# ATSAMA5D27WLSOM1 device description
Architecture: CORTEX-A5; Family: SAMA5; Series: SAMA5D2
Registers are 32-bit, read-write, no defined reset value unless marked. A register's access mark holds for its fields unless they carry their own. Offsets are from the block's base; [hi:lo] are bit positions; {n}, {i} and the like mark numbered series; 'fields as' and 'values as' point back to an identical list.

## LCDC — LCD Controller
Instances: LCDC 0xF0000000
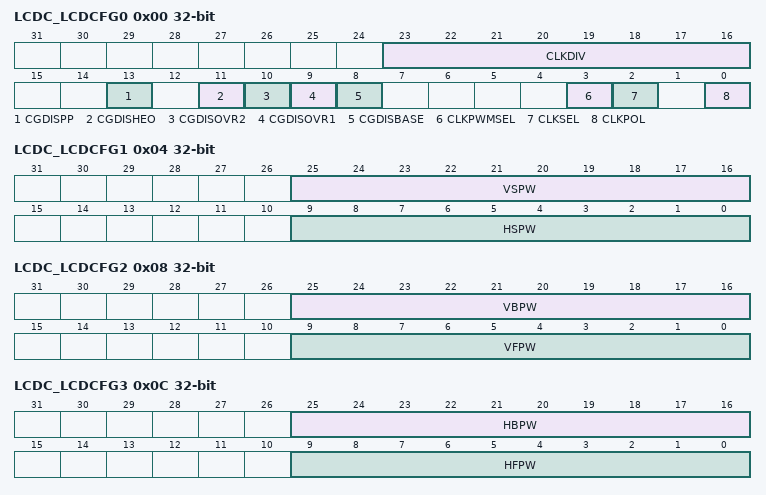
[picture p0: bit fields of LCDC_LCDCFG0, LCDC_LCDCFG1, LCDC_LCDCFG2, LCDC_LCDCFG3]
0x00 LCDC_LCDCFG0 — LCD Controller Configuration Register 0
  [23:16] CLKDIV — LCD Controller Clock Divider
  [13] CGDISPP — Clock Gating Disable Control for the Post Processing Layer
  [11] CGDISHEO — Clock Gating Disable Control for the High-End Overlay
  [10] CGDISOVR2 — Clock Gating Disable Control for the Overlay 2 Layer
  [9] CGDISOVR1 — Clock Gating Disable Control for the Overlay 1 Layer
  [8] CGDISBASE — Clock Gating Disable Control for the Base Layer
  [3] CLKPWMSEL — LCD Controller PWM Clock Source Selection
  [2] CLKSEL — LCD Controller Clock Source Selection
  [0] CLKPOL — LCD Controller Clock Polarity
0x04 LCDC_LCDCFG1 — LCD Controller Configuration Register 1
  [25:16] VSPW — Vertical Synchronization Pulse Width
  [9:0] HSPW — Horizontal Synchronization Pulse Width
0x08 LCDC_LCDCFG2 — LCD Controller Configuration Register 2
  [25:16] VBPW — Vertical Back Porch Width
  [9:0] VFPW — Vertical Front Porch Width
0x0C LCDC_LCDCFG3 — LCD Controller Configuration Register 3
  [25:16] HBPW — Horizontal Back Porch Width
  [9:0] HFPW — Horizontal Front Porch Width
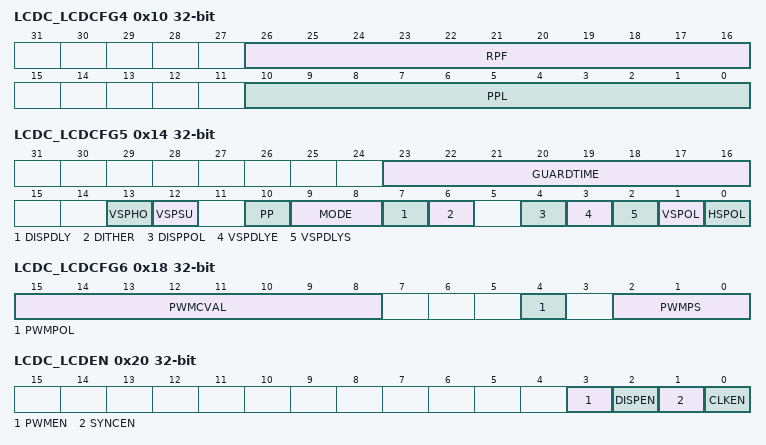
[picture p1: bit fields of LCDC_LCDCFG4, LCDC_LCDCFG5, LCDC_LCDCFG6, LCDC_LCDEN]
0x10 LCDC_LCDCFG4 — LCD Controller Configuration Register 4
  [26:16] RPF — Number of Active Row Per Frame
  [10:0] PPL — Number of Pixels Per Line
0x14 LCDC_LCDCFG5 — LCD Controller Configuration Register 5
  [23:16] GUARDTIME — LCD DISPLAY Guard Time
  [13] VSPHO — LCD Controller Vertical synchronization Pulse Hold Configuration
  [12] VSPSU — LCD Controller Vertical synchronization Pulse Setup Configuration
  [10] PP — Post Processing Enable
  [9:8] MODE — LCD Controller Output Mode
    0=OUTPUT_12BPP (LCD Output mode is set to 12 bits per pixel); 1=OUTPUT_16BPP (LCD Output mode is set to 16 bits per pixel); 2=OUTPUT_18BPP (LCD Output mode is set to 18 bits per pixel); 3=OUTPUT_24BPP (LCD Output mode is set to 24 bits per pixel)
  [7] DISPDLY — LCD Controller Display Power Signal Synchronization
  [6] DITHER — LCD Controller Dithering
  [4] DISPPOL — Display Signal Polarity
  [3] VSPDLYE — Vertical Synchronization Pulse End
  [2] VSPDLYS — Vertical Synchronization Pulse Start
  [1] VSPOL — Vertical Synchronization Pulse Polarity
  [0] HSPOL — Horizontal Synchronization Pulse Polarity
0x18 LCDC_LCDCFG6 — LCD Controller Configuration Register 6
  [15:8] PWMCVAL — LCD Controller PWM Compare Value
  [4] PWMPOL — LCD Controller PWM Signal Polarity
  [2:0] PWMPS — PWM Clock Prescaler
    0=DIV_1 (The counter advances at a rate of fCOUNTER = fPWM_SELECTED_CLOCK); 1=DIV_2 (The counter advances at a rate of fCOUNTER = fPWM_SELECTED_CLOCK/2); 2=DIV_4 (The counter advances at a rate of fCOUNTER = fPWM_SELECTED_CLOCK/4); 3=DIV_8 (The counter advances at a rate of fCOUNTER = fPWM_SELECTED_CLOCK/8); 4=DIV_16 (The counter advances at a rate of fCOUNTER = fPWM_SELECTED_CLOCK/16); 5=DIV_32 (The counter advances at a of rate fCOUNTER = fPWM_SELECTED_CLOCK/32); 6=DIV_64 (The counter advances at a of rate fCOUNTER = fPWM_SELECTED_CLOCK/64)
0x20 LCDC_LCDEN wo — LCD Controller Enable Register
  [3] PWMEN — LCD Controller Pulse Width Modulation Enable
  [2] DISPEN — LCD Controller DISP Signal Enable
  [1] SYNCEN — LCD Controller Horizontal and Vertical Synchronization Enable
  [0] CLKEN — LCD Controller Pixel Clock Enable
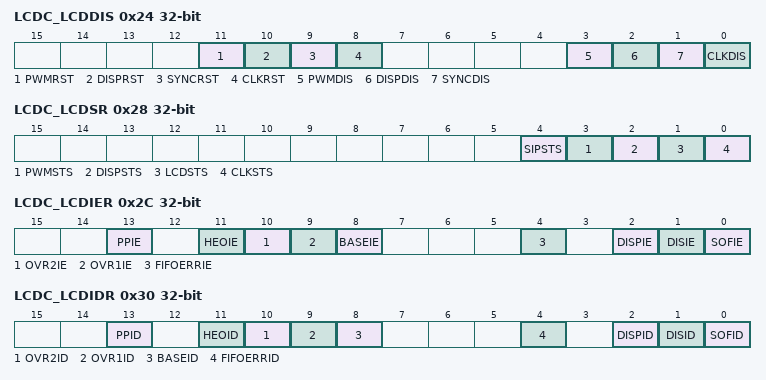
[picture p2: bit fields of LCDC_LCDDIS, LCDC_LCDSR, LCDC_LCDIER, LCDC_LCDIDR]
0x24 LCDC_LCDDIS wo — LCD Controller Disable Register
  [11] PWMRST — LCD Controller PWM Reset
  [10] DISPRST — LCD Controller DISP Signal Reset
  [9] SYNCRST — LCD Controller Horizontal and Vertical Synchronization Reset
  [8] CLKRST — LCD Controller Clock Reset
  [3] PWMDIS — LCD Controller Pulse Width Modulation Disable
  [2] DISPDIS — LCD Controller DISP Signal Disable
  [1] SYNCDIS — LCD Controller Horizontal and Vertical Synchronization Disable
  [0] CLKDIS — LCD Controller Pixel Clock Disable
0x28 LCDC_LCDSR ro — LCD Controller Status Register
  [4] SIPSTS — Synchronization In Progress
  [3] PWMSTS — LCD Controller PWM Signal Status
  [2] DISPSTS — LCD Controller DISP Signal Status
  [1] LCDSTS — LCD Controller Synchronization status
  [0] CLKSTS — Clock Status
0x2C LCDC_LCDIER wo — LCD Controller Interrupt Enable Register
  [13] PPIE — Post Processing Interrupt Enable
  [11] HEOIE — High-End Overlay Interrupt Enable
  [10] OVR2IE — Overlay 2 Interrupt Enable
  [9] OVR1IE — Overlay 1 Interrupt Enable
  [8] BASEIE — Base Layer Interrupt Enable
  [4] FIFOERRIE — Output FIFO Error Interrupt Enable
  [2] DISPIE — Powerup/Powerdown Sequence Terminated Interrupt Enable
  [1] DISIE — LCD Disable Interrupt Enable
  [0] SOFIE — Start of Frame Interrupt Enable
0x30 LCDC_LCDIDR wo — LCD Controller Interrupt Disable Register
  [13] PPID — Post Processing Interrupt Disable
  [11] HEOID — High-End Overlay Interrupt Disable
  [10] OVR2ID — Overlay 2 Interrupt Disable
  [9] OVR1ID — Overlay 1 Interrupt Disable
  [8] BASEID — Base Layer Interrupt Disable
  [4] FIFOERRID — Output FIFO Error Interrupt Disable
  [2] DISPID — Powerup/Powerdown Sequence Terminated Interrupt Disable
  [1] DISID — LCD Disable Interrupt Disable
  [0] SOFID — Start of Frame Interrupt Disable
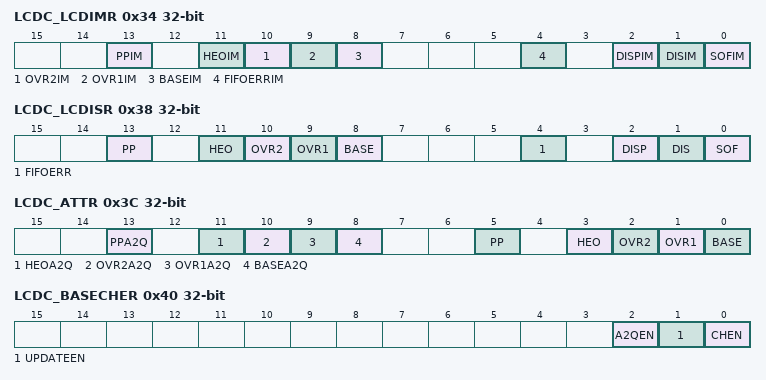
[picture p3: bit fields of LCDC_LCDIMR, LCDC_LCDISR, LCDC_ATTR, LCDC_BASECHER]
0x34 LCDC_LCDIMR ro — LCD Controller Interrupt Mask Register
  [13] PPIM — Post Processing Interrupt Mask
  [11] HEOIM — High-End Overlay Interrupt Mask
  [10] OVR2IM — Overlay 2 Interrupt Mask
  [9] OVR1IM — Overlay 1 Interrupt Mask
  [8] BASEIM — Base Layer Interrupt Mask
  [4] FIFOERRIM — Output FIFO Error Interrupt Mask
  [2] DISPIM — Powerup/Powerdown Sequence Terminated Interrupt Mask
  [1] DISIM — LCD Disable Interrupt Mask
  [0] SOFIM — Start of Frame Interrupt Mask
0x38 LCDC_LCDISR ro — LCD Controller Interrupt Status Register
  [13] PP — Post Processing Raw Interrupt Status
  [11] HEO — High-End Overlay Raw Interrupt Status
  [10] OVR2 — Overlay 2 Raw Interrupt Status
  [9] OVR1 — Overlay 1 Raw Interrupt Status
  [8] BASE — Base Layer Raw Interrupt Status
  [4] FIFOERR — Output FIFO Error
  [2] DISP — Powerup/Powerdown Sequence Terminated Interrupt Status
  [1] DIS — LCD Disable Interrupt Status
  [0] SOF — Start of Frame Interrupt Status
0x3C LCDC_ATTR wo — LCD Controller Attribute Register
  [13] PPA2Q — Post-Processing Update Add To Queue
  [11] HEOA2Q — High-End Overlay Update Add To Queue
  [10] OVR2A2Q — Overlay 2 Update Add to Queue
  [9] OVR1A2Q — Overlay 1 Update Add To Queue
  [8] BASEA2Q — Base Layer Update Add To Queue
  [5] PP — Post-Processing Update Attribute
  [3] HEO — High-End Overlay Update Attribute
  [2] OVR2 — Overlay 2 Update Attribute
  [1] OVR1 — Overlay 1 Update Attribute
  [0] BASE — Base Layer Update Attribute
0x40 LCDC_BASECHER wo — Base Layer Channel Enable Register
  [2] A2QEN — Add To Queue Enable
  [1] UPDATEEN — Update Overlay Attributes Enable
  [0] CHEN — Channel Enable
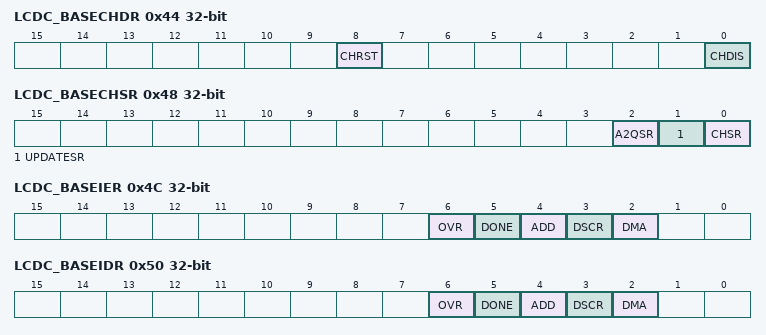
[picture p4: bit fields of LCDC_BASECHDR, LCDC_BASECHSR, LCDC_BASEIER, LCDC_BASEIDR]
0x44 LCDC_BASECHDR wo — Base Layer Channel Disable Register
  [8] CHRST — Channel Reset
  [0] CHDIS — Channel Disable
0x48 LCDC_BASECHSR ro — Base Layer Channel Status Register
  [2] A2QSR — Add To Queue Status
  [1] UPDATESR — Update Overlay Attributes In Progress Status
  [0] CHSR — Channel Status
0x4C LCDC_BASEIER wo — Base Layer Interrupt Enable Register
  [6] OVR — Overflow Interrupt Enable
  [5] DONE — End of List Interrupt Enable
  [4] ADD — Head Descriptor Loaded Interrupt Enable
  [3] DSCR — Descriptor Loaded Interrupt Enable
  [2] DMA — End of DMA Transfer Interrupt Enable
0x50 LCDC_BASEIDR wo — Base Layer Interrupt Disabled Register
  [6] OVR — Overflow Interrupt Disable
  [5] DONE — End of List Interrupt Disable
  [4] ADD — Head Descriptor Loaded Interrupt Disable
  [3] DSCR — Descriptor Loaded Interrupt Disable
  [2] DMA — End of DMA Transfer Interrupt Disable
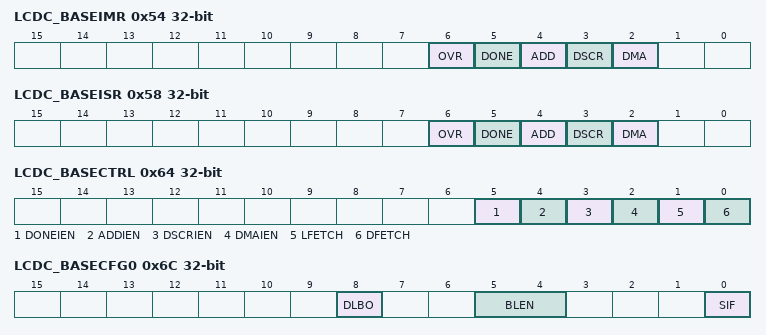
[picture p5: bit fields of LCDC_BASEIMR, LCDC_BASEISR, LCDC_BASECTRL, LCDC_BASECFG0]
0x54 LCDC_BASEIMR ro — Base Layer Interrupt Mask Register
  [6] OVR — Overflow Interrupt Mask
  [5] DONE — End of List Interrupt Mask
  [4] ADD — Head Descriptor Loaded Interrupt Mask
  [3] DSCR — Descriptor Loaded Interrupt Mask
  [2] DMA — End of DMA Transfer Interrupt Mask
0x58 LCDC_BASEISR ro — Base Layer Interrupt Status Register
  [6] OVR — Overflow Detected
  [5] DONE — End of List Detected
  [4] ADD — Head Descriptor Loaded
  [3] DSCR — DMA Descriptor Loaded
  [2] DMA — End of DMA Transfer
0x5C LCDC_BASEHEAD — Base DMA Head Register
  [31:2] HEAD — DMA Head Pointer
0x60 LCDC_BASEADDR — Base DMA Address Register
  [31:0] ADDR — DMA Transfer Start Address
0x64 LCDC_BASECTRL — Base DMA Control Register
  [5] DONEIEN — End of List Interrupt Enable
  [4] ADDIEN — Add Head Descriptor to Queue Interrupt Enable
  [3] DSCRIEN — Descriptor Loaded Interrupt Enable
  [2] DMAIEN — End of DMA Transfer Interrupt Enable
  [1] LFETCH — Lookup Table Fetch Enable
  [0] DFETCH — Transfer Descriptor Fetch Enable
0x68 LCDC_BASENEXT — Base DMA Next Register
  [31:0] NEXT — DMA Descriptor Next Address
0x6C LCDC_BASECFG0 — Base Layer Configuration Register 0
  [8] DLBO — Defined Length Burst Only For Channel Bus Transaction
  [5:4] BLEN — AHB Burst Length
    0=AHB_SINGLE (AHB Access is started as soon as there is enough space in the FIFO to store one data. SINGLE, INCR, INCR4, INCR8 and INCR16 bursts are used. INCR is used for a burst of 2 and 3 beats.); 1=AHB_INCR4 (AHB Access is started as soon as there is enough space in the FIFO to store a total amount of 4 data. An AHB INCR4 Burst is used. SINGLE, INCR and INCR4 bursts are used. INCR is used for a burst of 2 and 3 beats.); 2=AHB_INCR8 (AHB Access is started as soon as there is enough space in the FIFO to store a total amount of 8 data. An AHB INCR8 Burst is used. SINGLE, INCR, INCR4 and INCR8 bursts are used. INCR is used for a burst of 2 and 3 beats.); 3=AHB_INCR16 (AHB Access is started as soon as there is enough space in the FIFO to store a total amount of 16 data. An AHB INCR16 Burst is used. SINGLE, INCR, INCR4, INCR8 and INCR16 bursts are used. INCR is used for a burst of 2 and 3 beats.)
  [0] SIF — Source Interface
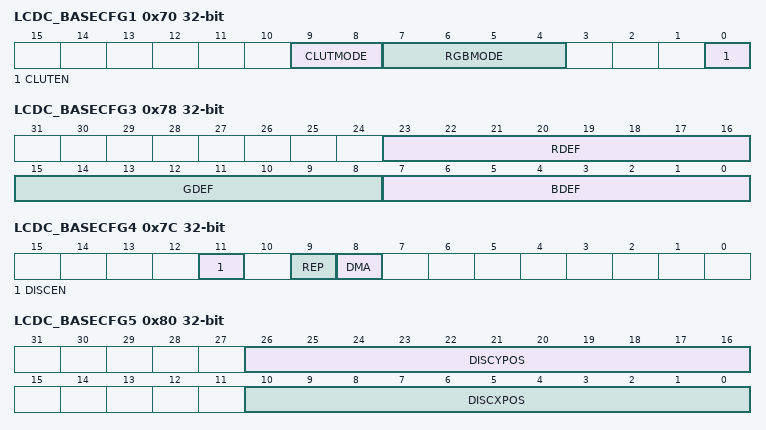
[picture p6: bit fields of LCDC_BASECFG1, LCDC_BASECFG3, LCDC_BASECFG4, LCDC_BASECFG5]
0x70 LCDC_BASECFG1 — Base Layer Configuration Register 1
  [9:8] CLUTMODE — Color Lookup Table Mode Input Selection
    0=CLUT_1BPP (Color Lookup Table mode set to 1 bit per pixel); 1=CLUT_2BPP (Color Lookup Table mode set to 2 bits per pixel); 2=CLUT_4BPP (Color Lookup Table mode set to 4 bits per pixel); 3=CLUT_8BPP (Color Lookup Table mode set to 8 bits per pixel)
  [7:4] RGBMODE — RGB Mode Input Selection
    0=_12BPP_RGB_444; 1=_16BPP_ARGB_4444; 2=_16BPP_RGBA_4444; 3=_16BPP_RGB_565; 4=_16BPP_TRGB_1555; 5=_18BPP_RGB_666; 6=_18BPP_RGB_666PACKED; 7=_19BPP_TRGB_1666; 8=_19BPP_TRGB_PACKED (19 bpp TRGB 1666 PACKED); 9=_24BPP_RGB_888; 10=_24BPP_RGB_888_PACKED; 11=_25BPP_TRGB_1888; 12=_32BPP_ARGB_8888; 13=_32BPP_RGBA_8888
  [0] CLUTEN — Color Lookup Table Mode Enable
0x74 LCDC_BASECFG2 — Base Layer Configuration Register 2
  [31:0] XSTRIDE — Horizontal Stride
0x78 LCDC_BASECFG3 — Base Layer Configuration Register 3
  [23:16] RDEF — Red Default
  [15:8] GDEF — Green Default
  [7:0] BDEF — Blue Default
0x7C LCDC_BASECFG4 — Base Layer Configuration Register 4
  [11] DISCEN — Discard Area Enable
  [9] REP — Use Replication logic to expand RGB color to 24 bits
  [8] DMA — Use DMA Data Path
0x80 LCDC_BASECFG5 — Base Layer Configuration Register 5
  [26:16] DISCYPOS — Discard Area Vertical Coordinate
  [10:0] DISCXPOS — Discard Area Horizontal Coordinate
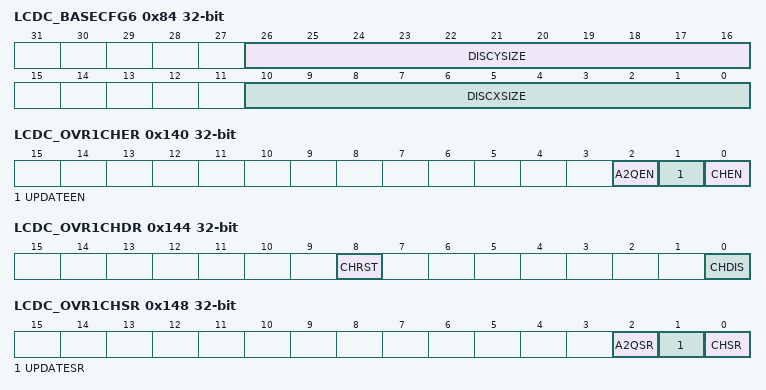
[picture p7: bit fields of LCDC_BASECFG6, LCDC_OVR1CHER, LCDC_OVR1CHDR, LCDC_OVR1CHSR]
0x84 LCDC_BASECFG6 — Base Layer Configuration Register 6
  [26:16] DISCYSIZE — Discard Area Vertical Size
  [10:0] DISCXSIZE — Discard Area Horizontal Size
0x140 LCDC_OVR1CHER wo — Overlay 1 Channel Enable Register
  fields as LCDC_BASECHER
0x144 LCDC_OVR1CHDR wo — Overlay 1 Channel Disable Register
  [8] CHRST — Channel Reset
  [0] CHDIS — Channel Disable
0x148 LCDC_OVR1CHSR ro — Overlay 1 Channel Status Register
  fields as LCDC_BASECHSR
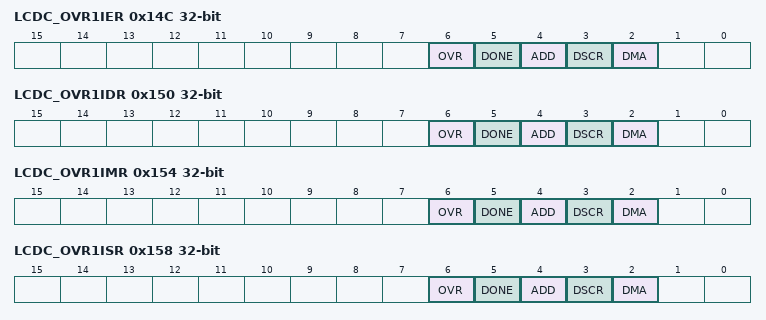
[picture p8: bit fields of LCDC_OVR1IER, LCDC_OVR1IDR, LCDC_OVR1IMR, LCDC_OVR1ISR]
0x14C LCDC_OVR1IER wo — Overlay 1 Interrupt Enable Register
  fields as LCDC_BASEIER
0x150 LCDC_OVR1IDR wo — Overlay 1 Interrupt Disable Register
  fields as LCDC_BASEIDR
0x154 LCDC_OVR1IMR ro — Overlay 1 Interrupt Mask Register
  fields as LCDC_BASEIMR
0x158 LCDC_OVR1ISR ro — Overlay 1 Interrupt Status Register
  fields as LCDC_BASEISR
0x15C LCDC_OVR1HEAD — Overlay 1 DMA Head Register
  [31:2] HEAD — DMA Head Pointer
0x160 LCDC_OVR1ADDR — Overlay 1 DMA Address Register
  [31:0] ADDR — DMA Transfer Overlay 1 Address
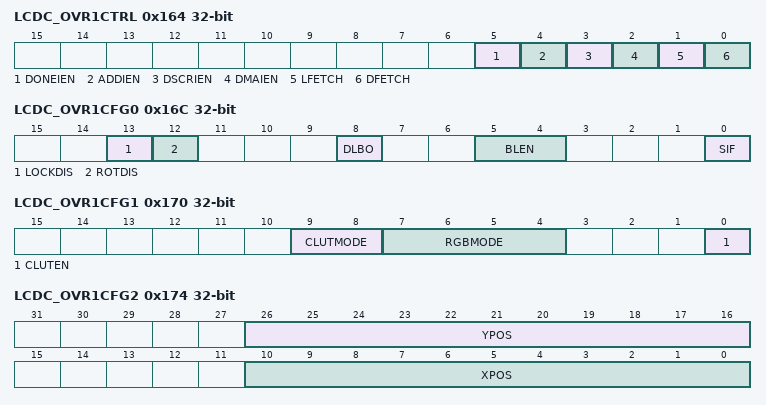
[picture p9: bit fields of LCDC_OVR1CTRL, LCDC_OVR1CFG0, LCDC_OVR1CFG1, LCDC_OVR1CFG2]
0x164 LCDC_OVR1CTRL — Overlay 1 DMA Control Register
  fields as LCDC_BASECTRL
0x168 LCDC_OVR1NEXT — Overlay 1 DMA Next Register
  [31:0] NEXT — DMA Descriptor Next Address
0x16C LCDC_OVR1CFG0 — Overlay 1 Configuration Register 0
  [13] LOCKDIS — Hardware Rotation Lock Disable
  [12] ROTDIS — Hardware Rotation Optimization Disable
  [8] DLBO — Defined Length Burst Only for Channel Bus Transaction
  [5:4] BLEN — AHB Burst Length
    0=AHB_BLEN_SINGLE (AHB Access is started as soon as there is enough space in the FIFO to store one data. SINGLE, INCR, INCR4, INCR8 and INCR16 bursts are used. INCR is used for a burst of 2 and 3 beats.); 1=AHB_BLEN_INCR4 (AHB Access is started as soon as there is enough space in the FIFO to store a total amount of 4 data. An AHB INCR4 Burst is used. SINGLE, INCR and INCR4 bursts are used. INCR is used for a burst of 2 and 3 beats.); 2=AHB_BLEN_INCR8 (AHB Access is started as soon as there is enough space in the FIFO to store a total amount of 8 data. An AHB INCR8 Burst is used. SINGLE, INCR, INCR4 and INCR8 bursts are used. INCR is used for a burst of 2 and 3 beats.); 3=AHB_BLEN_INCR16 (AHB Access is started as soon as there is enough space in the FIFO to store a total amount of 16 data. An AHB INCR16 Burst is used. SINGLE, INCR, INCR4, INCR8 and INCR16 bursts are used. INCR is used for a burst of 2 and 3 beats.)
  [0] SIF — Source Interface
0x170 LCDC_OVR1CFG1 — Overlay 1 Configuration Register 1
  fields as LCDC_BASECFG1
0x174 LCDC_OVR1CFG2 — Overlay 1 Configuration Register 2
  [26:16] YPOS — Vertical Window Position
  [10:0] XPOS — Horizontal Window Position
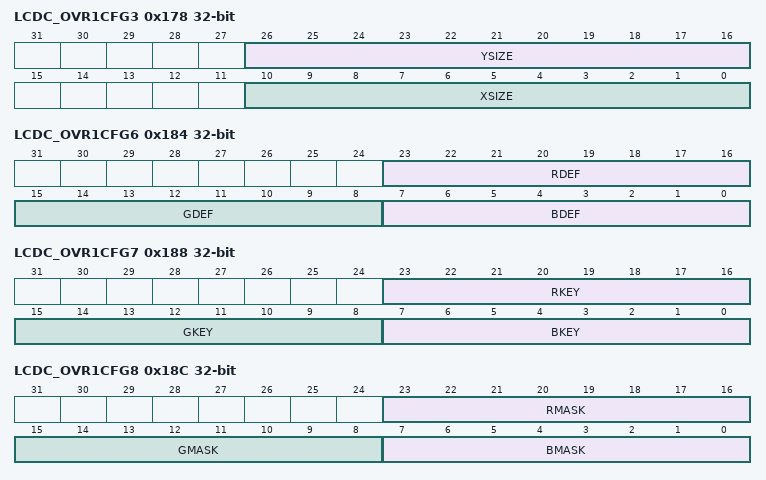
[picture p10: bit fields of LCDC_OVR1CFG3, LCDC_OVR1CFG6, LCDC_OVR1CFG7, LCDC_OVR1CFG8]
0x178 LCDC_OVR1CFG3 — Overlay 1 Configuration Register 3
  [26:16] YSIZE — Vertical Window Size
  [10:0] XSIZE — Horizontal Window Size
0x17C LCDC_OVR1CFG4 — Overlay 1 Configuration Register 4
  [31:0] XSTRIDE — Horizontal Stride
0x180 LCDC_OVR1CFG5 — Overlay 1 Configuration Register 5
  [31:0] PSTRIDE — Pixel Stride
0x184 LCDC_OVR1CFG6 — Overlay 1 Configuration Register 6
  fields as LCDC_BASECFG3
0x188 LCDC_OVR1CFG7 — Overlay 1 Configuration Register 7
  [23:16] RKEY — Red Color Component Chroma Key
  [15:8] GKEY — Green Color Component Chroma Key
  [7:0] BKEY — Blue Color Component Chroma Key
0x18C LCDC_OVR1CFG8 — Overlay 1 Configuration Register 8
  [23:16] RMASK — Red Color Component Chroma Key Mask
  [15:8] GMASK — Green Color Component Chroma Key Mask
  [7:0] BMASK — Blue Color Component Chroma Key Mask
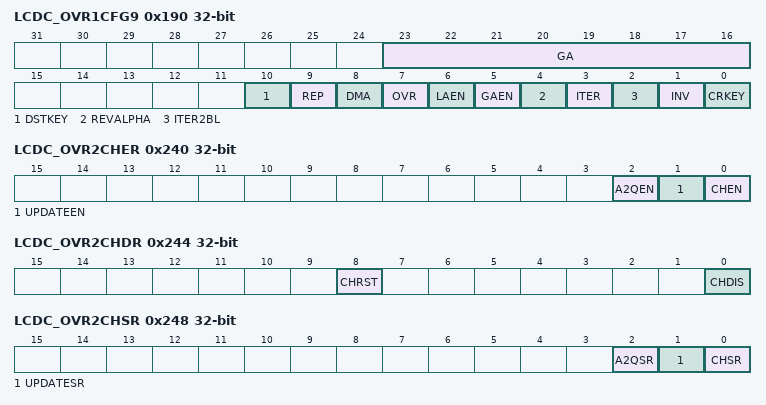
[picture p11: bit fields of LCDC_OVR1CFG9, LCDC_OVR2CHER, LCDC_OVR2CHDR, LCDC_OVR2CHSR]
0x190 LCDC_OVR1CFG9 — Overlay 1 Configuration Register 9
  [23:16] GA — Blender Global Alpha
  [10] DSTKEY — Destination Chroma Keying
  [9] REP — Use Replication logic to expand RGB color to 24 bits
  [8] DMA — Blender DMA Layer Enable
  [7] OVR — Blender Overlay Layer Enable
  [6] LAEN — Blender Local Alpha Enable
  [5] GAEN — Blender Global Alpha Enable
  [4] REVALPHA — Blender Reverse Alpha
  [3] ITER — Blender Use Iterated Color
  [2] ITER2BL — Blender Iterated Color Enable
  [1] INV — Blender Inverted Blender Output Enable
  [0] CRKEY — Blender Chroma Key Enable
0x240 LCDC_OVR2CHER wo — Overlay 2 Channel Enable Register
  fields as LCDC_BASECHER
0x244 LCDC_OVR2CHDR wo — Overlay 2 Channel Disable Register
  [8] CHRST — Channel Reset
  [0] CHDIS — Channel Disable
0x248 LCDC_OVR2CHSR ro — Overlay 2 Channel Status Register
  fields as LCDC_BASECHSR
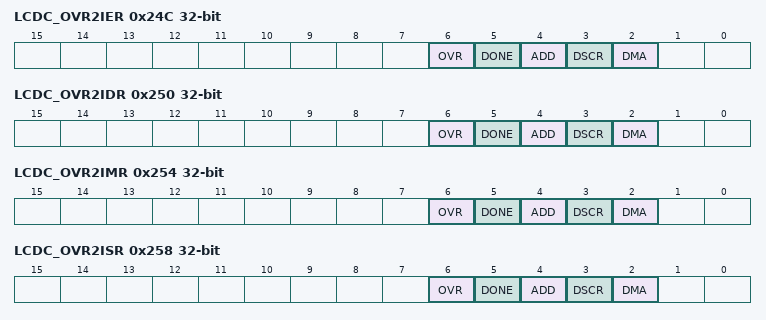
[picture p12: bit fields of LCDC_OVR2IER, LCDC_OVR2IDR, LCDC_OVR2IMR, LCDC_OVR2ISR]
0x24C LCDC_OVR2IER wo — Overlay 2 Interrupt Enable Register
  fields as LCDC_BASEIER
0x250 LCDC_OVR2IDR wo — Overlay 2 Interrupt Disable Register
  fields as LCDC_BASEIDR
0x254 LCDC_OVR2IMR ro — Overlay 2 Interrupt Mask Register
  fields as LCDC_BASEIMR
0x258 LCDC_OVR2ISR ro — Overlay 2 Interrupt Status Register
  fields as LCDC_BASEISR
0x25C LCDC_OVR2HEAD — Overlay 2 DMA Head Register
  [31:2] HEAD — DMA Head Pointer
0x260 LCDC_OVR2ADDR — Overlay 2 DMA Address Register
  [31:0] ADDR — DMA Transfer Overlay 2 Address
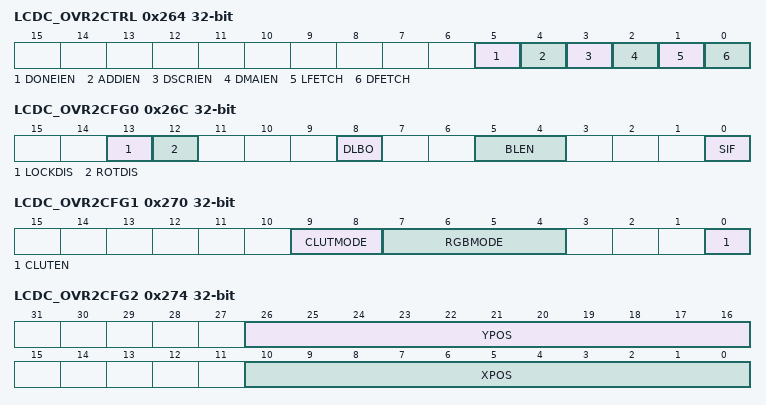
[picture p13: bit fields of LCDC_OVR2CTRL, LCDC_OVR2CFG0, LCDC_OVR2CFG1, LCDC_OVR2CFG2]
0x264 LCDC_OVR2CTRL — Overlay 2 DMA Control Register
  fields as LCDC_BASECTRL
0x268 LCDC_OVR2NEXT — Overlay 2 DMA Next Register
  [31:0] NEXT — DMA Descriptor Next Address
0x26C LCDC_OVR2CFG0 — Overlay 2 Configuration Register 0
  [13] LOCKDIS — Hardware Rotation Lock Disable
  [12] ROTDIS — Hardware Rotation Optimization Disable
  [8] DLBO — Defined Length Burst Only For Channel Bus Transaction
  [5:4] BLEN — AHB Burst Length
    values as LCDC_BASECFG0.BLEN
  [0] SIF — Source Interface
    0=Overlay 2 data is retrieved through System Bus interface 0; 1=Overlay 2 data is retrieved through System Bus interface 1
0x270 LCDC_OVR2CFG1 — Overlay 2 Configuration Register 1
  fields as LCDC_BASECFG1
0x274 LCDC_OVR2CFG2 — Overlay 2 Configuration Register 2
  fields as LCDC_OVR1CFG2
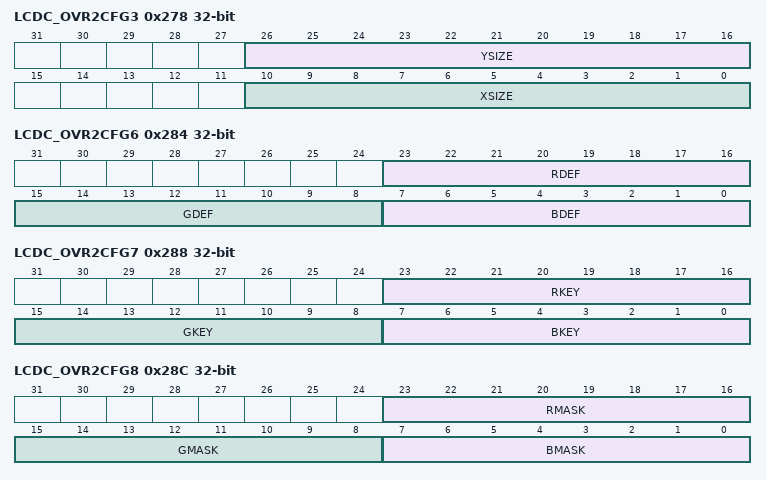
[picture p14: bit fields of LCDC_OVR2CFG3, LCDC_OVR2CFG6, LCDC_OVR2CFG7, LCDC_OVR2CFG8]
0x278 LCDC_OVR2CFG3 — Overlay 2 Configuration Register 3
  fields as LCDC_OVR1CFG3
0x27C LCDC_OVR2CFG4 — Overlay 2 Configuration Register 4
  [31:0] XSTRIDE — Horizontal Stride
0x280 LCDC_OVR2CFG5 — Overlay 2 Configuration Register 5
  [31:0] PSTRIDE — Pixel Stride
0x284 LCDC_OVR2CFG6 — Overlay 2 Configuration Register 6
  fields as LCDC_BASECFG3
0x288 LCDC_OVR2CFG7 — Overlay 2 Configuration Register 7
  fields as LCDC_OVR1CFG7
0x28C LCDC_OVR2CFG8 — Overlay 2 Configuration Register 8
  fields as LCDC_OVR1CFG8
0x290 LCDC_OVR2CFG9 — Overlay 2 Configuration Register 9
  fields as LCDC_OVR1CFG9
0x340 LCDC_HEOCHER wo — High-End Overlay Channel Enable Register
  fields as LCDC_BASECHER
0x344 LCDC_HEOCHDR wo — High-End Overlay Channel Disable Register
  [8] CHRST — Channel Reset
  [0] CHDIS — Channel Disable
0x348 LCDC_HEOCHSR ro — High-End Overlay Channel Status Register
  fields as LCDC_BASECHSR
0x34C LCDC_HEOIER wo — High-End Overlay Interrupt Enable Register
  [22] VOVR — Overflow for V Chrominance Interrupt Enable
  [21] VDONE — End of List for V Chrominance Interrupt Enable
  [20] VADD — Head Descriptor Loaded for V Chrominance Interrupt Enable
  [19] VDSCR — Descriptor Loaded for V Chrominance Interrupt Enable
  [18] VDMA — End of DMA for V Chrominance Transfer Interrupt Enable
  [14] UOVR — Overflow for U or UV Chrominance Interrupt Enable
  [13] UDONE — End of List for U or UV Chrominance Interrupt Enable
  [12] UADD — Head Descriptor Loaded for U or UV Chrominance Interrupt Enable
  [11] UDSCR — Descriptor Loaded for U or UV Chrominance Interrupt Enable
  [10] UDMA — End of DMA Transfer for U or UV Chrominance Interrupt Enable
  [6] OVR — Overflow Interrupt Enable
  [5] DONE — End of List Interrupt Enable
  [4] ADD — Head Descriptor Loaded Interrupt Enable
  [3] DSCR — Descriptor Loaded Interrupt Enable
  [2] DMA — End of DMA Transfer Interrupt Enable
0x350 LCDC_HEOIDR wo — High-End Overlay Interrupt Disable Register
  [22] VOVR — Overflow for V Chrominance Component Interrupt Disable
  [21] VDONE — End of List for V Chrominance Component Interrupt Disable
  [20] VADD — Head Descriptor Loaded for V Chrominance Component Interrupt Disable
  [19] VDSCR — Descriptor Loaded for V Chrominance Component Interrupt Disable
  [18] VDMA — End of DMA Transfer for V Chrominance Component Interrupt Disable
  [14] UOVR — Overflow Interrupt for U or UV Chrominance Component Disable
  [13] UDONE — End of List Interrupt for U or UV Chrominance Component Disable
  [12] UADD — Head Descriptor Loaded for U or UV Chrominance Component Interrupt Disable
  [11] UDSCR — Descriptor Loaded for U or UV Chrominance Component Interrupt Disable
  [10] UDMA — End of DMA Transfer for U or UV Chrominance Component Interrupt Disable
  [6] OVR — Overflow Interrupt Disable
  [5] DONE — End of List Interrupt Disable
  [4] ADD — Head Descriptor Loaded Interrupt Disable
  [3] DSCR — Descriptor Loaded Interrupt Disable
  [2] DMA — End of DMA Transfer Interrupt Disable
0x354 LCDC_HEOIMR ro — High-End Overlay Interrupt Mask Register
  [22] VOVR — Overflow for V Chrominance Interrupt Mask
  [21] VDONE — End of List for V Chrominance Component Mask
  [20] VADD — Head Descriptor Loaded for V Chrominance Component Mask
  [19] VDSCR — Descriptor Loaded for V Chrominance Component Interrupt Mask
  [18] VDMA — End of DMA Transfer for V Chrominance Component Interrupt Mask
  [14] UOVR — Overflow for U Chrominance Interrupt Mask
  [13] UDONE — End of List for U or UV Chrominance Component Mask
  [12] UADD — Head Descriptor Loaded for U or UV Chrominance Component Mask
  [11] UDSCR — Descriptor Loaded for U or UV Chrominance Component Interrupt Mask
  [10] UDMA — End of DMA Transfer for U or UV Chrominance Component Interrupt Mask
  [6] OVR — Overflow Interrupt Mask
  [5] DONE — End of List Interrupt Mask
  [4] ADD — Head Descriptor Loaded Interrupt Mask
  [3] DSCR — Descriptor Loaded Interrupt Mask
  [2] DMA — End of DMA Transfer Interrupt Mask
0x358 LCDC_HEOISR ro — High-End Overlay Interrupt Status Register
  [22] VOVR — Overflow Detected for V Component
  [21] VDONE — End of List Detected for V Component
  [20] VADD — Head Descriptor Loaded for V Component
  [19] VDSCR — DMA Descriptor Loaded for V Component
  [18] VDMA — End of DMA Transfer for V Component
  [14] UOVR — Overflow Detected for U Component
  [13] UDONE — End of List Detected for U Component
  [12] UADD — Head Descriptor Loaded for U Component
  [11] UDSCR — DMA Descriptor Loaded for U Component
  [10] UDMA — End of DMA Transfer for U Component
  [6] OVR — Overflow Detected
  [5] DONE — End of List Detected
  [4] ADD — Head Descriptor Loaded
  [3] DSCR — DMA Descriptor Loaded
  [2] DMA — End of DMA Transfer
0x35C LCDC_HEOHEAD — High-End Overlay DMA Head Register
  [31:2] HEAD — DMA Head Pointer
0x360 LCDC_HEOADDR — High-End Overlay DMA Address Register
  [31:0] ADDR — DMA Transfer Start Address
0x364 LCDC_HEOCTRL — High-End Overlay DMA Control Register
  fields as LCDC_BASECTRL
0x368 LCDC_HEONEXT — High-End Overlay DMA Next Register
  [31:0] NEXT — DMA Descriptor Next Address
0x36C LCDC_HEOUHEAD — High-End Overlay U-UV DMA Head Register
  [31:0] UHEAD — DMA Head Pointer
0x370 LCDC_HEOUADDR — High-End Overlay U-UV DMA Address Register
  [31:0] UADDR — DMA Transfer Start Address for U or UV Chrominance
0x374 LCDC_HEOUCTRL — High-End Overlay U-UV DMA Control Register
  [5] UDONEIEN — End of List Interrupt Enable
  [4] UADDIEN — Add Head Descriptor to Queue Interrupt Enable
  [3] UDSCRIEN — Descriptor Loaded Interrupt Enable
  [2] UDMAIEN — End of DMA Transfer Interrupt Enable
  [0] UDFETCH — Transfer Descriptor Fetch Enable
0x378 LCDC_HEOUNEXT — High-End Overlay U-UV DMA Next Register
  [31:0] UNEXT — DMA Descriptor Next Address
0x37C LCDC_HEOVHEAD — High-End Overlay V DMA Head Register
  [31:0] VHEAD — DMA Head Pointer
0x380 LCDC_HEOVADDR — High-End Overlay V DMA Address Register
  [31:0] VADDR — DMA Transfer Start Address for V Chrominance
0x384 LCDC_HEOVCTRL — High-End Overlay V DMA Control Register
  [5] VDONEIEN — End of List Interrupt Enable
  [4] VADDIEN — Add Head Descriptor to Queue Interrupt Enable
  [3] VDSCRIEN — Descriptor Loaded Interrupt Enable
  [2] VDMAIEN — End of DMA Transfer Interrupt Enable
  [0] VDFETCH — Transfer Descriptor Fetch Enable
0x388 LCDC_HEOVNEXT — High-End Overlay V DMA Next Register
  [31:0] VNEXT — DMA Descriptor Next Address
0x38C LCDC_HEOCFG0 — High-End Overlay Configuration Register 0
  [13] LOCKDIS — Hardware Rotation Lock Disable
  [12] ROTDIS — Hardware Rotation Optimization Disable
  [8] DLBO — Defined Length Burst Only For Channel Bus Transaction
  [7:6] BLENUV — AHB Burst Length for U-V Channel
    values as LCDC_BASECFG0.BLEN
  [5:4] BLEN — AHB Burst Length
    values as LCDC_OVR1CFG0.BLEN
  [0] SIF — Source Interface
0x390 LCDC_HEOCFG1 — High-End Overlay Configuration Register 1
  [20] DSCALEOPT — Down Scaling Bandwidth Optimization
  [17] YUV422SWP — YUV 4:2:2 Swap
  [16] YUV422ROT — YUV 4:2:2 Rotation
  [15:12] YUVMODE — YUV Mode Input Selection
  [9:8] CLUTMODE — Color Lookup Table Mode Input Selection
    values as LCDC_BASECFG1.CLUTMODE
  [7:4] RGBMODE — RGB Mode Input Selection
    values as LCDC_BASECFG1.RGBMODE
  [1] YUVEN — YUV Color Space Enable
  [0] CLUTEN — Color Lookup Table Mode Enable
0x394 LCDC_HEOCFG2 — High-End Overlay Configuration Register 2
  fields as LCDC_OVR1CFG2
0x398 LCDC_HEOCFG3 — High-End Overlay Configuration Register 3
  fields as LCDC_OVR1CFG3
0x39C LCDC_HEOCFG4 — High-End Overlay Configuration Register 4
  [26:16] YMEMSIZE — Vertical image Size in Memory
  [10:0] XMEMSIZE — Horizontal image Size in Memory
0x3A0 LCDC_HEOCFG5 — High-End Overlay Configuration Register 5
  [31:0] XSTRIDE — Horizontal Stride
0x3A4 LCDC_HEOCFG6 — High-End Overlay Configuration Register 6
  [31:0] PSTRIDE — Pixel Stride
0x3A8 LCDC_HEOCFG7 — High-End Overlay Configuration Register 7
  [31:0] UVXSTRIDE — UV Horizontal Stride
0x3AC LCDC_HEOCFG8 — High-End Overlay Configuration Register 8
  [31:0] UVPSTRIDE — UV Pixel Stride
0x3B0 LCDC_HEOCFG9 — High-End Overlay Configuration Register 9
  fields as LCDC_BASECFG3
0x3B4 LCDC_HEOCFG10 — High-End Overlay Configuration Register 10
  fields as LCDC_OVR1CFG7
0x3B8 LCDC_HEOCFG11 — High-End Overlay Configuration Register 11
  fields as LCDC_OVR1CFG8
0x3BC LCDC_HEOCFG12 — High-End Overlay Configuration Register 12
  [23:16] GA — Blender Global Alpha
  [12] VIDPRI — Video Priority
  [10] DSTKEY — Destination Chroma Keying
  [9] REP — Use Replication logic to expand RGB color to 24 bits
  [8] DMA — Blender DMA Layer Enable
  [7] OVR — Blender Overlay Layer Enable
  [6] LAEN — Blender Local Alpha Enable
  [5] GAEN — Blender Global Alpha Enable
  [4] REVALPHA — Blender Reverse Alpha
  [3] ITER — Blender Use Iterated Color
  [2] ITER2BL — Blender Iterated Color Enable
  [1] INV — Blender Inverted Blender Output Enable
  [0] CRKEY — Blender Chroma Key Enable
0x3C0 LCDC_HEOCFG13 — High-End Overlay Configuration Register 13
  [31] SCALEN — Hardware Scaler Enable
  [29:16] YFACTOR — Vertical Scaling Factor
  [13:0] XFACTOR — Horizontal Scaling Factor
0x3C4 LCDC_HEOCFG14 — High-End Overlay Configuration Register 14
  [30] CSCYOFF — Color Space Conversion Offset
  [29:20] CSCRV — Color Space Conversion V coefficient for Red Component 1:2:7 format
  [19:10] CSCRU — Color Space Conversion U coefficient for Red Component 1:2:7 format
  [9:0] CSCRY — Color Space Conversion Y coefficient for Red Component 1:2:7 format
0x3C8 LCDC_HEOCFG15 — High-End Overlay Configuration Register 15
  [30] CSCUOFF — Color Space Conversion Offset
  [29:20] CSCGV — Color Space Conversion V coefficient for Green Component 1:2:7 format
  [19:10] CSCGU — Color Space Conversion U coefficient for Green Component 1:2:7 format
  [9:0] CSCGY — Color Space Conversion Y coefficient for Green Component 1:2:7 format
0x3CC LCDC_HEOCFG16 — High-End Overlay Configuration Register 16
  [30] CSCVOFF — Color Space Conversion Offset
  [29:20] CSCBV — Color Space Conversion V coefficient for Blue Component 1:2:7 format
  [19:10] CSCBU — Color Space Conversion U coefficient for Blue Component 1:2:7 format
  [9:0] CSCBY — Color Space Conversion Y coefficient for Blue Component 1:2:7 format
0x3D0 LCDC_HEOCFG17 — High-End Overlay Configuration Register 17
  [8n+7:8n] XPHI0COEFF{n} (n=0..3) — Horizontal Coefficient for phase 0 tap {n}
0x3D4 LCDC_HEOCFG18 — High-End Overlay Configuration Register 18
  [7:0] XPHI0COEFF4 — Horizontal Coefficient for phase 0 tap 4
0x3D8 LCDC_HEOCFG19 — High-End Overlay Configuration Register 19
  [8n+7:8n] XPHI1COEFF{n} (n=0..3) — Horizontal Coefficient for phase 1 tap {n}
0x3DC LCDC_HEOCFG20 — High-End Overlay Configuration Register 20
  [7:0] XPHI1COEFF4 — Horizontal Coefficient for phase 1 tap 4
0x3E0 LCDC_HEOCFG21 — High-End Overlay Configuration Register 21
  [8n+7:8n] XPHI2COEFF{n} (n=0..3) — Horizontal Coefficient for phase 2 tap {n}
0x3E4 LCDC_HEOCFG22 — High-End Overlay Configuration Register 22
  [7:0] XPHI2COEFF4 — Horizontal Coefficient for phase 2 tap 4
0x3E8 LCDC_HEOCFG23 — High-End Overlay Configuration Register 23
  [8n+7:8n] XPHI3COEFF{n} (n=0..3) — Horizontal Coefficient for phase 3 tap {n}
0x3EC LCDC_HEOCFG24 — High-End Overlay Configuration Register 24
  [7:0] XPHI3COEFF4 — Horizontal Coefficient for phase 3 tap 4
0x3F0 LCDC_HEOCFG25 — High-End Overlay Configuration Register 25
  [8n+7:8n] XPHI4COEFF{n} (n=0..3) — Horizontal Coefficient for phase 4 tap {n}
0x3F4 LCDC_HEOCFG26 — High-End Overlay Configuration Register 26
  [7:0] XPHI4COEFF4 — Horizontal Coefficient for phase 4 tap 4
0x3F8 LCDC_HEOCFG27 — High-End Overlay Configuration Register 27
  [8n+7:8n] XPHI5COEFF{n} (n=0..3) — Horizontal Coefficient for phase 5 tap {n}
0x3FC LCDC_HEOCFG28 — High-End Overlay Configuration Register 28
  [7:0] XPHI5COEFF4 — Horizontal Coefficient for phase 5 tap 4
0x400 LCDC_HEOCFG29 — High-End Overlay Configuration Register 29
  [8n+7:8n] XPHI6COEFF{n} (n=0..3) — Horizontal Coefficient for phase 6 tap {n}
0x404 LCDC_HEOCFG30 — High-End Overlay Configuration Register 30
  [7:0] XPHI6COEFF4 — Horizontal Coefficient for phase 6 tap 4
0x408 LCDC_HEOCFG31 — High-End Overlay Configuration Register 31
  [8n+7:8n] XPHI7COEFF{n} (n=0..3) — Horizontal Coefficient for phase 7 tap {n}
0x40C LCDC_HEOCFG32 — High-End Overlay Configuration Register 32
  [7:0] XPHI7COEFF4 — Horizontal Coefficient for phase 7 tap 4
{0x38C+4i} LCDC_HEOCFG{i} (i=33..40) — High-End Overlay Configuration Register {i}
  [23:16] YPHI{i-33}COEFF2 — Vertical Coefficient for phase {i-33} tap 2
  [15:8] YPHI{i-33}COEFF1 — Vertical Coefficient for phase {i-33} tap 1
  [7:0] YPHI{i-33}COEFF0 — Vertical Coefficient for phase {i-33} tap 0
0x430 LCDC_HEOCFG41 — High-End Overlay Configuration Register 41
  [18:16] YPHIDEF — Vertical Filter Phase Offset
  [2:0] XPHIDEF — Horizontal Filter Phase Offset
0x540 LCDC_PPCHER wo — Post Processing Channel Enable Register
  fields as LCDC_BASECHER
0x544 LCDC_PPCHDR wo — Post Processing Channel Disable Register
  [8] CHRST — Channel Reset
  [0] CHDIS — Channel Disable
0x548 LCDC_PPCHSR ro — Post Processing Channel Status Register
  fields as LCDC_BASECHSR
0x54C LCDC_PPIER wo — Post Processing Interrupt Enable Register
  [5] DONE — End of List Interrupt Enable
  [4] ADD — Head Descriptor Loaded Interrupt Enable
  [3] DSCR — Descriptor Loaded Interrupt Enable
  [2] DMA — End of DMA Transfer Interrupt Enable
0x550 LCDC_PPIDR wo — Post Processing Interrupt Disable Register
  [5] DONE — End of List Interrupt Disable
  [4] ADD — Head Descriptor Loaded Interrupt Disable
  [3] DSCR — Descriptor Loaded Interrupt Disable
  [2] DMA — End of DMA Transfer Interrupt Disable
0x554 LCDC_PPIMR ro — Post Processing Interrupt Mask Register
  [5] DONE — End of List Interrupt Mask
  [4] ADD — Head Descriptor Loaded Interrupt Mask
  [3] DSCR — Descriptor Loaded Interrupt Mask
  [2] DMA — End of DMA Transfer Interrupt Mask
0x558 LCDC_PPISR ro — Post Processing Interrupt Status Register
  [5] DONE — End of List Detected
  [4] ADD — Head Descriptor Loaded
  [3] DSCR — DMA Descriptor Loaded
  [2] DMA — End of DMA Transfer
0x55C LCDC_PPHEAD — Post Processing Head Register
  [31:2] HEAD — DMA Head Pointer
0x560 LCDC_PPADDR — Post Processing Address Register
  [31:0] ADDR — DMA Transfer Start Address
0x564 LCDC_PPCTRL — Post Processing Control Register
  [5] DONEIEN — End of List Interrupt Enable
  [4] ADDIEN — Add Head Descriptor to Queue Interrupt Enable
  [3] DSCRIEN — Descriptor Loaded Interrupt Enable
  [2] DMAIEN — End of DMA Transfer Interrupt Enable
  [0] DFETCH — Transfer Descriptor Fetch Enable
0x568 LCDC_PPNEXT — Post Processing Next Register
  [31:0] NEXT — DMA Descriptor Next Address
0x56C LCDC_PPCFG0 — Post Processing Configuration Register 0
  [8] DLBO — Defined Length Burst Only For Channel Bus Transaction
  [5:4] BLEN — AHB Burst Length
  [0] SIF — Source Interface
0x570 LCDC_PPCFG1 — Post Processing Configuration Register 1
  [4] ITUBT601 — Color Space Conversion Luminance
  [2:0] PPMODE — Post Processing Output Format Selection
    0=PPMODE_RGB_16BPP (RGB 16 bpp); 1=PPMODE_RGB_24BPP_PACKED (RGB 24 bpp PACKED); 2=PPMODE_RGB_24BPP_UNPACKED (RGB 24 bpp UNPACKED); {v}=PPMODE_YCBCR_422_MODE{v-3} (YCbCr 422 16 bpp (Mode {v-3})) (v=3..6)
0x574 LCDC_PPCFG2 — Post Processing Configuration Register 2
  [31:0] XSTRIDE — Horizontal Stride
0x578 LCDC_PPCFG3 — Post Processing Configuration Register 3
  [30] CSCYOFF — Color Space Conversion Luminance Offset
  [29:20] CSCYB — Color Space Conversion B coefficient for Luminance component, signed format, step set to 1/1024
  [19:10] CSCYG — Color Space Conversion G coefficient for Luminance component, signed format, step set to 1/512
  [9:0] CSCYR — Color Space Conversion R coefficient for Luminance component, signed format, step set to 1/1024
0x57C LCDC_PPCFG4 — Post Processing Configuration Register 4
  [30] CSCUOFF — Color Space Conversion Chrominance B Offset
  [29:20] CSCUB — Color Space Conversion B coefficient for Chrominance B component, signed format. (step 1/512)
  [19:10] CSCUG — Color Space Conversion G coefficient for Chrominance B component, signed format. (step 1/512)
  [9:0] CSCUR — Color Space Conversion R coefficient for Chrominance B component, signed format. (step 1/1024)
0x580 LCDC_PPCFG5 — Post Processing Configuration Register 5
  [30] CSCVOFF — Color Space Conversion Chrominance R Offset
  [29:20] CSCVB — Color Space Conversion B coefficient for Chrominance R component, signed format. (step 1/1024)
  [19:10] CSCVG — Color Space Conversion G coefficient for Chrominance R component, signed format. (step 1/512)
  [9:0] CSCVR — Color Space Conversion R coefficient for Chrominance R component, signed format. (step 1/1024)
{0x600+4i} LCDC_BASECLUT[{i}] (i=0..255) — Base CLUT Register
  [23:16] RCLUT — Red Color Entry
  [15:8] GCLUT — Green Color Entry
  [7:0] BCLUT — Blue Color Entry
{0xA00+4i} LCDC_OVR1CLUT[{i}] (i=0..255) — Overlay 1 CLUT Register
  [31:24] ACLUT — Alpha Color Entry
  [23:16] RCLUT — Red Color Entry
  [15:8] GCLUT — Green Color Entry
  [7:0] BCLUT — Blue Color Entry
{0xE00+4i} LCDC_OVR2CLUT[{i}] (i=0..255) — Overlay 2 CLUT Register
  fields as LCDC_OVR1CLUT[0]
{0x1200+4i} LCDC_HEOCLUT[{i}] (i=0..255) — High-End Overlay CLUT Register
  fields as LCDC_OVR1CLUT[0]
